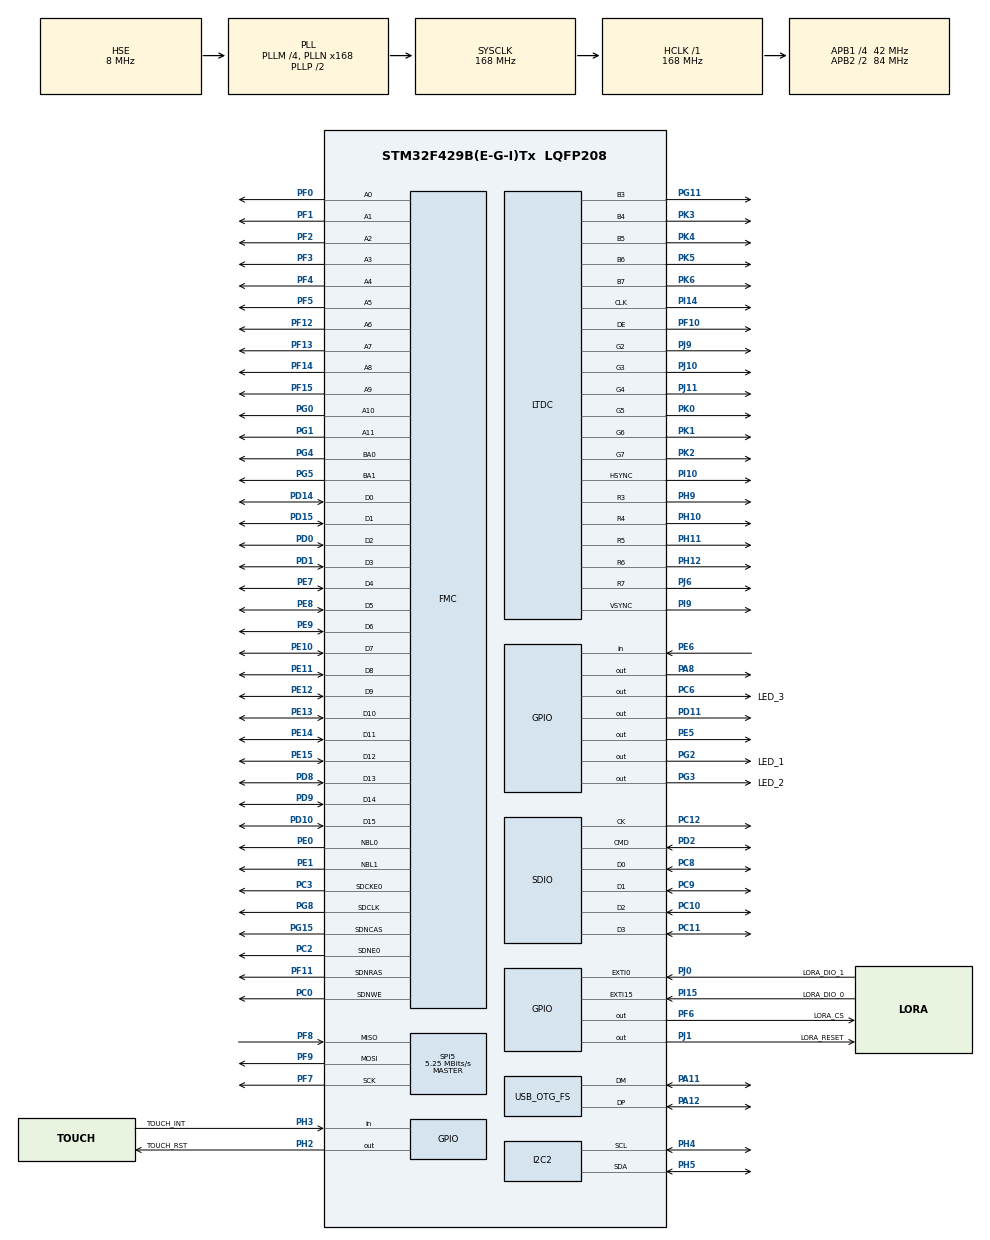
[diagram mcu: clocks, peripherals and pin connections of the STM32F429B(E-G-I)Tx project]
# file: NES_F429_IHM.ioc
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FATFS.BSP.number=1
FATFS0.BSP.STBoard=false
FATFS0.BSP.api=Unknown
FATFS0.BSP.instance=PE6
FATFS0.BSP.ip=GPIO
FATFS0.BSP.mode=Input
FATFS0.BSP.name=Detect_SDIO
FATFS0.BSP.solution=PE6
FMC.CASLatency1=FMC_SDRAM_CAS_LATENCY_3
FMC.ExitSelfRefreshDelay1=7
FMC.LoadToActiveDelay1=2
FMC.RCDDelay1=2
FMC.RPDelay1=2
FMC.RPDelay2=2
FMC.ReadPipeDelay1=FMC_SDRAM_RPIPE_DELAY_1
FMC.ReadPipeDelay2=FMC_SDRAM_RPIPE_DELAY_1
FMC.RowCycleDelay1=6
FMC.RowCycleDelay2=6
FMC.SDClockPeriod1=FMC_SDRAM_CLOCK_PERIOD_2
FMC.SDClockPeriod2=FMC_SDRAM_CLOCK_PERIOD_2
FMC.SelfRefreshTime1=4
FMC.WriteRecoveryTime1=2
I2C2.I2C_Mode=I2C_Fast
LTDC.ActiveH=272
LTDC.ActiveW=480
LTDC.Alpha_L0=255
LTDC.FBStartAdress_L0=0xC0000000
LTDC.HBP=2
LTDC.HFP=2
LTDC.HSync=17
LTDC.ImageHeight_L0=272
LTDC.ImageWidth_L0=480
LTDC.Layers=0
LTDC.PixelFormat_L0=LTDC_PIXEL_FORMAT_RGB565
LTDC.VBP=2
LTDC.VFP=2
LTDC.VSync=60
LTDC.WindowX1_L0=480
LTDC.WindowY1_L0=272
Mcu.Family=STM32F4
Mcu.Name=STM32F429B(E-G-I)Tx
Mcu.Package=LQFP208
NVIC.EXTI0_IRQn=true\:0\:0\:false\:false\:true\:true\:true\:true
NVIC.EXTI15_10_IRQn=true\:0\:0\:false\:false\:true\:true\:true\:true
NVIC.OTG_FS_IRQn=true\:0\:0\:false\:false\:true\:false\:true\:true
NVIC.PriorityGroup=NVIC_PRIORITYGROUP_4
NVIC.TIM8_TRG_COM_TIM14_IRQn=true\:15\:0\:false\:false\:true\:false\:true\:true
NVIC.TimeBase=TIM8_TRG_COM_TIM14_IRQn
NVIC.TimeBaseIP=TIM14
PA11.Mode=Host_Only
PA11.Signal=USB_OTG_FS_DM
PA12.Mode=Host_Only
PA12.Signal=USB_OTG_FS_DP
PA13.Mode=Serial_Wire
PA13.Signal=SYS_JTMS-SWDIO
PA14.Mode=Serial_Wire
PA14.Signal=SYS_JTCK-SWCLK
PA8.PinState=GPIO_PIN_SET
PA8.Signal=GPIO_Output
PC0.Signal=FMC_SDNWE
PC10.Mode=SD_4_bits_Wide_bus
PC10.Signal=SDIO_D2
PC11.Mode=SD_4_bits_Wide_bus
PC11.Signal=SDIO_D3
PC12.Mode=SD_4_bits_Wide_bus
PC12.Signal=SDIO_CK
PC2.Mode=SdramChipSelect1_1
PC2.Signal=FMC_SDNE0
PC3.Mode=SdramChipSelect1_1
PC3.Signal=FMC_SDCKE0
PC6.GPIO_Label=LED_3
PC6.Signal=GPIO_Output
PC8.Mode=SD_4_bits_Wide_bus
PC8.Signal=SDIO_D0
PC9.Mode=SD_4_bits_Wide_bus
PC9.Signal=SDIO_D1
PD0.Signal=FMC_D2_DA2
PD1.Signal=FMC_D3_DA3
PD10.Signal=FMC_D15_DA15
PD11.PinState=GPIO_PIN_SET
PD11.Signal=GPIO_Output
PD14.Signal=FMC_D0_DA0
PD15.Signal=FMC_D1_DA1
PD2.Mode=SD_4_bits_Wide_bus
PD2.Signal=SDIO_CMD
PD8.Signal=FMC_D13_DA13
PD9.Signal=FMC_D14_DA14
PE0.Signal=FMC_NBL0
PE1.Signal=FMC_NBL1
PE10.Signal=FMC_D7_DA7
PE11.Signal=FMC_D8_DA8
PE12.Signal=FMC_D9_DA9
PE13.Signal=FMC_D10_DA10
PE14.Signal=FMC_D11_DA11
PE15.Signal=FMC_D12_DA12
PE5.Signal=GPIO_Output
PE6.Signal=GPIO_Input
PE7.Signal=FMC_D4_DA4
PE8.Signal=FMC_D5_DA5
PE9.Signal=FMC_D6_DA6
PF0.Signal=FMC_A0
PF1.Signal=FMC_A1
PF10.GPIO_Speed=GPIO_SPEED_FREQ_VERY_HIGH
PF10.Mode=RGB565
PF10.Signal=LTDC_DE
PF11.Signal=FMC_SDNRAS
PF12.Signal=FMC_A6
PF13.Signal=FMC_A7
PF14.Signal=FMC_A8
PF15.Signal=FMC_A9
PF2.Signal=FMC_A2
PF3.Signal=FMC_A3
PF4.Signal=FMC_A4
PF5.Signal=FMC_A5
PF6.GPIO_Label=LORA_CS
PF6.Signal=GPIO_Output
PF7.GPIO_PuPd=GPIO_PULLUP
PF7.Mode=Full_Duplex_Master
PF7.Signal=SPI5_SCK
PF8.GPIO_PuPd=GPIO_PULLUP
PF8.Mode=Full_Duplex_Master
PF8.Signal=SPI5_MISO
PF9.GPIO_PuPd=GPIO_PULLUP
PF9.Mode=Full_Duplex_Master
PF9.Signal=SPI5_MOSI
PG0.Signal=FMC_A10
PG1.Signal=FMC_A11
PG11.GPIO_Speed=GPIO_SPEED_FREQ_VERY_HIGH
PG11.Mode=RGB565
PG11.Signal=LTDC_B3
PG15.Signal=FMC_SDNCAS
PG2.GPIO_Label=LED_1
PG2.Signal=GPIO_Output
PG3.GPIO_Label=LED_2
PG3.Signal=GPIO_Output
PG4.Signal=FMC_A14_BA0
PG5.Signal=FMC_A15_BA1
PG8.Signal=FMC_SDCLK
PH0/OSC_IN.Mode=HSE-External-Oscillator
PH0/OSC_IN.Signal=RCC_OSC_IN
PH1/OSC_OUT.Mode=HSE-External-Oscillator
PH1/OSC_OUT.Signal=RCC_OSC_OUT
PH10.GPIO_Speed=GPIO_SPEED_FREQ_VERY_HIGH
PH10.Mode=RGB565
PH10.Signal=LTDC_R4
PH11.GPIO_Speed=GPIO_SPEED_FREQ_VERY_HIGH
PH11.Mode=RGB565
PH11.Signal=LTDC_R5
PH12.GPIO_Speed=GPIO_SPEED_FREQ_VERY_HIGH
PH12.Mode=RGB565
PH12.Signal=LTDC_R6
PH2.GPIO_Label=TOUCH_RST
PH2.Signal=GPIO_Output
PH3.GPIO_Label=TOUCH_INT
PH3.Signal=GPIO_Input
PH4.GPIO_Pu=GPIO_PULLUP
PH4.Mode=I2C
PH4.Signal=I2C2_SCL
PH5.GPIO_Pu=GPIO_PULLUP
PH5.Mode=I2C
PH5.Signal=I2C2_SDA
PH9.GPIO_Speed=GPIO_SPEED_FREQ_VERY_HIGH
PH9.Mode=RGB565
PH9.Signal=LTDC_R3
PI10.GPIO_Speed=GPIO_SPEED_FREQ_VERY_HIGH
PI10.Mode=RGB565
PI10.Signal=LTDC_HSYNC
PI14.GPIO_Speed=GPIO_SPEED_FREQ_VERY_HIGH
PI14.Mode=RGB565
PI14.Signal=LTDC_CLK
PI15.GPIO_Label=LORA_DIO_0
PI15.Signal=GPXTI15
PI9.GPIO_Speed=GPIO_SPEED_FREQ_VERY_HIGH
PI9.Mode=RGB565
PI9.Signal=LTDC_VSYNC
PJ0.GPIO_Label=LORA_DIO_1
PJ0.Signal=GPXTI0
PJ1.GPIO_Label=LORA_RESET
PJ1.Signal=GPIO_Output
PJ10.GPIO_Speed=GPIO_SPEED_FREQ_VERY_HIGH
PJ10.Mode=RGB565
PJ10.Signal=LTDC_G3
PJ11.GPIO_Speed=GPIO_SPEED_FREQ_VERY_HIGH
PJ11.Mode=RGB565
PJ11.Signal=LTDC_G4
PJ6.GPIO_Speed=GPIO_SPEED_FREQ_VERY_HIGH
PJ6.Mode=RGB565
PJ6.Signal=LTDC_R7
PJ9.GPIO_Speed=GPIO_SPEED_FREQ_VERY_HIGH
PJ9.Mode=RGB565
PJ9.Signal=LTDC_G2
PK0.GPIO_Speed=GPIO_SPEED_FREQ_VERY_HIGH
PK0.Mode=RGB565
PK0.Signal=LTDC_G5
PK1.GPIO_Speed=GPIO_SPEED_FREQ_VERY_HIGH
PK1.Mode=RGB565
PK1.Signal=LTDC_G6
PK2.GPIO_Speed=GPIO_SPEED_FREQ_VERY_HIGH
PK2.Mode=RGB565
PK2.Signal=LTDC_G7
PK3.GPIO_Speed=GPIO_SPEED_FREQ_VERY_HIGH
PK3.Mode=RGB565
PK3.Signal=LTDC_B4
PK4.GPIO_Speed=GPIO_SPEED_FREQ_VERY_HIGH
PK4.Mode=RGB565
PK4.Signal=LTDC_B5
PK5.GPIO_Speed=GPIO_SPEED_FREQ_VERY_HIGH
PK5.Mode=RGB565
PK5.Signal=LTDC_B6
PK6.GPIO_Speed=GPIO_SPEED_FREQ_VERY_HIGH
PK6.Mode=RGB565
PK6.Signal=LTDC_B7
ProjectManager.HeapSize=0x200
ProjectManager.StackSize=0x400
ProjectManager.TargetToolchain=STM32CubeIDE
RCC.48MHZClocksFreq_Value=48000000
RCC.AHBFreq_Value=168000000
RCC.APB1CLKDivider=RCC_HCLK_DIV4
RCC.APB1Freq_Value=42000000
RCC.APB1TimFreq_Value=84000000
RCC.APB2CLKDivider=RCC_HCLK_DIV2
RCC.APB2Freq_Value=84000000
RCC.APB2TimFreq_Value=168000000
RCC.CortexFreq_Value=168000000
RCC.HCLKFreq_Value=168000000
RCC.HSE_VALUE=8000000
RCC.HSI_VALUE=16000000
RCC.LSE_VALUE=32768
RCC.PLLM=4
RCC.PLLN=168
RCC.PLLQ=7
RCC.PLLSAIDivR=RCC_PLLSAIDIVR_4
RCC.PLLSAIN=80
RCC.PLLSAIR=4
RCC.PWREXT_OverDrive=PWREXT_OverDrive_ACTIVATED
RCC.PWR_Regulator_Voltage_Scale=PWR_REGULATOR_VOLTAGE_SCALE1
RCC.SYSCLKFreq_VALUE=168000000
RCC.SYSCLKSource=RCC_SYSCLKSOURCE_PLLCLK
RCC.VCOOutputFreq_Value=336000000
SDIO.ClockDiv=10
SH.FMC_A0.0=FMC_A0,12b-sda1
SH.FMC_A1.0=FMC_A1,12b-sda1
SH.FMC_A10.0=FMC_A10,12b-sda1
SH.FMC_A11.0=FMC_A11,12b-sda1
SH.FMC_A14_BA0.0=FMC_BA0,FourSdramBanks1
SH.FMC_A15_BA1.0=FMC_BA1,FourSdramBanks1
SH.FMC_A2.0=FMC_A2,12b-sda1
SH.FMC_A3.0=FMC_A3,12b-sda1
SH.FMC_A4.0=FMC_A4,12b-sda1
SH.FMC_A5.0=FMC_A5,12b-sda1
SH.FMC_A6.0=FMC_A6,12b-sda1
SH.FMC_A7.0=FMC_A7,12b-sda1
SH.FMC_A8.0=FMC_A8,12b-sda1
SH.FMC_A9.0=FMC_A9,12b-sda1
SH.FMC_D0_DA0.0=FMC_D0,sd-16b-d1
SH.FMC_D10_DA10.0=FMC_D10,sd-16b-d1
SH.FMC_D11_DA11.0=FMC_D11,sd-16b-d1
SH.FMC_D12_DA12.0=FMC_D12,sd-16b-d1
SH.FMC_D13_DA13.0=FMC_D13,sd-16b-d1
SH.FMC_D14_DA14.0=FMC_D14,sd-16b-d1
SH.FMC_D15_DA15.0=FMC_D15,sd-16b-d1
SH.FMC_D1_DA1.0=FMC_D1,sd-16b-d1
SH.FMC_D2_DA2.0=FMC_D2,sd-16b-d1
SH.FMC_D3_DA3.0=FMC_D3,sd-16b-d1
SH.FMC_D4_DA4.0=FMC_D4,sd-16b-d1
SH.FMC_D5_DA5.0=FMC_D5,sd-16b-d1
SH.FMC_D6_DA6.0=FMC_D6,sd-16b-d1
SH.FMC_D7_DA7.0=FMC_D7,sd-16b-d1
SH.FMC_D8_DA8.0=FMC_D8,sd-16b-d1
SH.FMC_D9_DA9.0=FMC_D9,sd-16b-d1
SH.FMC_NBL0.0=FMC_NBL0,Sd2ByteEnable1
SH.FMC_NBL1.0=FMC_NBL1,Sd2ByteEnable1
SH.FMC_SDCLK.0=FMC_SDCLK,12b-sda1
SH.FMC_SDNCAS.0=FMC_SDNCAS,12b-sda1
SH.FMC_SDNRAS.0=FMC_SDNRAS,12b-sda1
SH.FMC_SDNWE.0=FMC_SDNWE,12b-sda1
SPI5.BaudRatePrescaler=SPI_BAUDRATEPRESCALER_16
SPI5.CalculateBaudRate=5.25 MBits/s
SPI5.Direction=SPI_DIRECTION_2LINES
SPI5.Mode=SPI_MODE_MASTER
SPI5.VirtualType=VM_MASTER
USB_HOST.BSP.number=1
USB_HOST.USBH_HandleTypeDef-ALL_Classes_FS=hUsbHostFS
USB_HOST.VirtualModeFS=All_Classes
USB_HOST0.BSP.STBoard=false
USB_HOST0.BSP.api=Unknown
USB_HOST0.BSP.instance=PE5
USB_HOST0.BSP.ip=GPIO
USB_HOST0.BSP.mode=Output
USB_HOST0.BSP.name=Drive_VBUS_FS
USB_HOST0.BSP.solution=PE5
USB_OTG_FS.VirtualMode=Host_Only
USB_OTG_FS.phy_itface=HCD_PHY_EMBEDDED
VP_FATFS_VS_SDIO.Mode=SDIO
VP_SYS_VS_tim14.Mode=TIM14
VP_USB_HOST_VS_USB_HOST_ALL_CLASS_FS.Mode=ALL_Classes_FS
board=custom

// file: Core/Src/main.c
/* USER CODE BEGIN Header */
/**
 ******************************************************************************
 * @file           : main.c
 * @brief          : Main program body
 ******************************************************************************
 * @attention
 *
 * Copyright (c) 2022 STMicroelectronics.
 * All rights reserved.
 *
 * This software is licensed under terms that can be found in the LICENSE file
 * in the root directory of this software component.
 * If no LICENSE file comes with this software, it is provided AS-IS.
 *
 ******************************************************************************
 */
/* USER CODE END Header */
#include "main.h"
#include "fatfs.h"
#include "usb_host.h"

/* USER CODE BEGIN Includes */
#include <stdlib.h>
#include <stdbool.h>
#include <stdint.h>
#include <stdarg.h>
#include <string.h>
#include "ReturnCode.h"
#include "nes.h"
#include "fatfs.h"
/* USER CODE END Includes */

I2C_HandleTypeDef hi2c2;

LTDC_HandleTypeDef hltdc;

SD_HandleTypeDef hsd;

SPI_HandleTypeDef hspi5;

SDRAM_HandleTypeDef hsdram1;

/* USER CODE BEGIN PV */
extern uint16_t * framebuffer;

/* USER CODE END PV */

void SystemClock_Config(void);
static void MX_GPIO_Init(void);
static void MX_FMC_Init(void);
static void MX_LTDC_Init(void);
static void MX_I2C2_Init(void);
static void MX_SPI5_Init(void);
static void MX_SDIO_SD_Init(void);
void MX_USB_HOST_Process(void);

/* USER CODE BEGIN PFP */
extern const uint8_t MAIO[];
static FRESULT fr;
/* USER CODE END PFP */

int main(void)
{

  /* MCU Configuration--------------------------------------------------------*/

  /* Reset of all peripherals, Initializes the Flash interface and the Systick. */
  HAL_Init();

  /* Configure the system clock */
  SystemClock_Config();

  /* Initialize all configured peripherals */
  MX_GPIO_Init();
  MX_FMC_Init();
  MX_LTDC_Init();
  MX_I2C2_Init();
  MX_SPI5_Init();
  MX_SDIO_SD_Init();
  MX_FATFS_Init();
  MX_USB_HOST_Init();
  /* USER CODE BEGIN 2 */
  fr = f_mount(&SDFatFS, "", 0);

  for(int y = 0; y < 272; y++)
  {
	  for(int x = 0; x < 480; x++)
	  {
		  framebuffer[y * 480 + x] = 0;
	  }
  }

  nofrendo_start(MAIO, NES_NTSC, 6000, 0);

  /* USER CODE END 2 */

  /* Infinite loop */
  /* USER CODE BEGIN WHILE */
	while (1)
	{

		//nes_emulate();
    /* USER CODE END WHILE */
    MX_USB_HOST_Process();

	}
}

void SystemClock_Config(void)
{
  RCC_OscInitTypeDef RCC_OscInitStruct = {0};
  RCC_ClkInitTypeDef RCC_ClkInitStruct = {0};

  /** Configure the main internal regulator output voltage
  */
  __HAL_RCC_PWR_CLK_ENABLE();
  __HAL_PWR_VOLTAGESCALING_CONFIG(PWR_REGULATOR_VOLTAGE_SCALE1);

  /** Initializes the RCC Oscillators according to the specified parameters
  * in the RCC_OscInitTypeDef structure.
  */
  RCC_OscInitStruct.OscillatorType = RCC_OSCILLATORTYPE_HSE;
  RCC_OscInitStruct.HSEState = RCC_HSE_ON;
  RCC_OscInitStruct.PLL.PLLState = RCC_PLL_ON;
  RCC_OscInitStruct.PLL.PLLSource = RCC_PLLSOURCE_HSE;
  RCC_OscInitStruct.PLL.PLLM = 4;
  RCC_OscInitStruct.PLL.PLLN = 168;
  RCC_OscInitStruct.PLL.PLLP = RCC_PLLP_DIV2;
  RCC_OscInitStruct.PLL.PLLQ = 7;
  if (HAL_RCC_OscConfig(&RCC_OscInitStruct) != HAL_OK)
  {
    Error_Handler();
  }

  /** Activate the Over-Drive mode
  */
  if (HAL_PWREx_EnableOverDrive() != HAL_OK)
  {
    Error_Handler();
  }

  /** Initializes the CPU, AHB and APB buses clocks
  */
  RCC_ClkInitStruct.ClockType = RCC_CLOCKTYPE_HCLK|RCC_CLOCKTYPE_SYSCLK
                              |RCC_CLOCKTYPE_PCLK1|RCC_CLOCKTYPE_PCLK2;
  RCC_ClkInitStruct.SYSCLKSource = RCC_SYSCLKSOURCE_PLLCLK;
  RCC_ClkInitStruct.AHBCLKDivider = RCC_SYSCLK_DIV1;
  RCC_ClkInitStruct.APB1CLKDivider = RCC_HCLK_DIV4;
  RCC_ClkInitStruct.APB2CLKDivider = RCC_HCLK_DIV2;

  if (HAL_RCC_ClockConfig(&RCC_ClkInitStruct, FLASH_LATENCY_5) != HAL_OK)
  {
    Error_Handler();
  }
}

static void MX_I2C2_Init(void)
{

  hi2c2.Instance = I2C2;
  hi2c2.Init.ClockSpeed = 400000;
  hi2c2.Init.DutyCycle = I2C_DUTYCYCLE_2;
  hi2c2.Init.OwnAddress1 = 0;
  hi2c2.Init.AddressingMode = I2C_ADDRESSINGMODE_7BIT;
  hi2c2.Init.DualAddressMode = I2C_DUALADDRESS_DISABLE;
  hi2c2.Init.OwnAddress2 = 0;
  hi2c2.Init.GeneralCallMode = I2C_GENERALCALL_DISABLE;
  hi2c2.Init.NoStretchMode = I2C_NOSTRETCH_DISABLE;
  if (HAL_I2C_Init(&hi2c2) != HAL_OK)
  {
    Error_Handler();
  }

  /** Configure Analogue filter
  */
  if (HAL_I2CEx_ConfigAnalogFilter(&hi2c2, I2C_ANALOGFILTER_ENABLE) != HAL_OK)
  {
    Error_Handler();
  }

  /** Configure Digital filter
  */
  if (HAL_I2CEx_ConfigDigitalFilter(&hi2c2, 0) != HAL_OK)
  {
    Error_Handler();
  }

}

static void MX_LTDC_Init(void)
{

  LTDC_LayerCfgTypeDef pLayerCfg = {0};

  hltdc.Instance = LTDC;
  hltdc.Init.HSPolarity = LTDC_HSPOLARITY_AL;
  hltdc.Init.VSPolarity = LTDC_VSPOLARITY_AL;
  hltdc.Init.DEPolarity = LTDC_DEPOLARITY_AL;
  hltdc.Init.PCPolarity = LTDC_PCPOLARITY_IPC;
  hltdc.Init.HorizontalSync = 16;
  hltdc.Init.VerticalSync = 59;
  hltdc.Init.AccumulatedHBP = 18;
  hltdc.Init.AccumulatedVBP = 61;
  hltdc.Init.AccumulatedActiveW = 498;
  hltdc.Init.AccumulatedActiveH = 333;
  hltdc.Init.TotalWidth = 500;
  hltdc.Init.TotalHeigh = 335;
  hltdc.Init.Backcolor.Blue = 0;
  hltdc.Init.Backcolor.Green = 0;
  hltdc.Init.Backcolor.Red = 0;
  if (HAL_LTDC_Init(&hltdc) != HAL_OK)
  {
    Error_Handler();
  }
  pLayerCfg.WindowX0 = 0;
  pLayerCfg.WindowX1 = 480;
  pLayerCfg.WindowY0 = 0;
  pLayerCfg.WindowY1 = 272;
  pLayerCfg.PixelFormat = LTDC_PIXEL_FORMAT_RGB565;
  pLayerCfg.Alpha = 255;
  pLayerCfg.Alpha0 = 0;
  pLayerCfg.BlendingFactor1 = LTDC_BLENDING_FACTOR1_CA;
  pLayerCfg.BlendingFactor2 = LTDC_BLENDING_FACTOR2_CA;
  pLayerCfg.FBStartAdress = 0xC0000000;
  pLayerCfg.ImageWidth = 480;
  pLayerCfg.ImageHeight = 272;
  pLayerCfg.Backcolor.Blue = 0;
  pLayerCfg.Backcolor.Green = 0;
  pLayerCfg.Backcolor.Red = 0;
  if (HAL_LTDC_ConfigLayer(&hltdc, &pLayerCfg, 0) != HAL_OK)
  {
    Error_Handler();
  }

}

static void MX_SDIO_SD_Init(void)
{

  hsd.Instance = SDIO;
  hsd.Init.ClockEdge = SDIO_CLOCK_EDGE_RISING;
  hsd.Init.ClockBypass = SDIO_CLOCK_BYPASS_DISABLE;
  hsd.Init.ClockPowerSave = SDIO_CLOCK_POWER_SAVE_DISABLE;
  hsd.Init.BusWide = SDIO_BUS_WIDE_1B;
  hsd.Init.HardwareFlowControl = SDIO_HARDWARE_FLOW_CONTROL_DISABLE;
  hsd.Init.ClockDiv = 10;

}

static void MX_SPI5_Init(void)
{

  /* SPI5 parameter configuration*/
  hspi5.Instance = SPI5;
  hspi5.Init.Mode = SPI_MODE_MASTER;
  hspi5.Init.Direction = SPI_DIRECTION_2LINES;
  hspi5.Init.DataSize = SPI_DATASIZE_8BIT;
  hspi5.Init.CLKPolarity = SPI_POLARITY_LOW;
  hspi5.Init.CLKPhase = SPI_PHASE_1EDGE;
  hspi5.Init.NSS = SPI_NSS_SOFT;
  hspi5.Init.BaudRatePrescaler = SPI_BAUDRATEPRESCALER_16;
  hspi5.Init.FirstBit = SPI_FIRSTBIT_MSB;
  hspi5.Init.TIMode = SPI_TIMODE_DISABLE;
  hspi5.Init.CRCCalculation = SPI_CRCCALCULATION_DISABLE;
  hspi5.Init.CRCPolynomial = 10;
  if (HAL_SPI_Init(&hspi5) != HAL_OK)
  {
    Error_Handler();
  }

}

/* FMC initialization function */
static void MX_FMC_Init(void)
{

  /* USER CODE BEGIN FMC_Init 0 */
#define REFRESH_COUNT        683
#define SDRAM_TIMEOUT                            ((uint32_t)0xFFFF)
#define SDRAM_MODEREG_BURST_LENGTH_1             ((uint16_t)0x0000)
#define SDRAM_MODEREG_BURST_LENGTH_2             ((uint16_t)0x0001)
#define SDRAM_MODEREG_BURST_LENGTH_4             ((uint16_t)0x0002)
#define SDRAM_MODEREG_BURST_LENGTH_8             ((uint16_t)0x0004)
#define SDRAM_MODEREG_BURST_TYPE_SEQUENTIAL      ((uint16_t)0x0000)
#define SDRAM_MODEREG_BURST_TYPE_INTERLEAVED     ((uint16_t)0x0008)
#define SDRAM_MODEREG_CAS_LATENCY_2              ((uint16_t)0x0020)
#define SDRAM_MODEREG_CAS_LATENCY_3              ((uint16_t)0x0030)
#define SDRAM_MODEREG_OPERATING_MODE_STANDARD    ((uint16_t)0x0000)
#define SDRAM_MODEREG_WRITEBURST_MODE_PROGRAMMED ((uint16_t)0x0000)
#define SDRAM_MODEREG_WRITEBURST_MODE_SINGLE     ((uint16_t)0x0200)
  /* USER CODE END FMC_Init 0 */

  FMC_SDRAM_TimingTypeDef SdramTiming = {0};

  /* USER CODE BEGIN FMC_Init 1 */
	FMC_SDRAM_CommandTypeDef Command;
  /* USER CODE END FMC_Init 1 */

  /** Perform the SDRAM1 memory initialization sequence
  */
  hsdram1.Instance = FMC_SDRAM_DEVICE;
  /* hsdram1.Init */
  hsdram1.Init.SDBank = FMC_SDRAM_BANK1;
  hsdram1.Init.ColumnBitsNumber = FMC_SDRAM_COLUMN_BITS_NUM_8;
  hsdram1.Init.RowBitsNumber = FMC_SDRAM_ROW_BITS_NUM_12;
  hsdram1.Init.MemoryDataWidth = FMC_SDRAM_MEM_BUS_WIDTH_16;
  hsdram1.Init.InternalBankNumber = FMC_SDRAM_INTERN_BANKS_NUM_4;
  hsdram1.Init.CASLatency = FMC_SDRAM_CAS_LATENCY_3;
  hsdram1.Init.WriteProtection = FMC_SDRAM_WRITE_PROTECTION_DISABLE;
  hsdram1.Init.SDClockPeriod = FMC_SDRAM_CLOCK_PERIOD_2;
  hsdram1.Init.ReadBurst = FMC_SDRAM_RBURST_DISABLE;
  hsdram1.Init.ReadPipeDelay = FMC_SDRAM_RPIPE_DELAY_1;
  /* SdramTiming */
  SdramTiming.LoadToActiveDelay = 2;
  SdramTiming.ExitSelfRefreshDelay = 7;
  SdramTiming.SelfRefreshTime = 4;
  SdramTiming.RowCycleDelay = 6;
  SdramTiming.WriteRecoveryTime = 2;
  SdramTiming.RPDelay = 2;
  SdramTiming.RCDDelay = 2;

  if (HAL_SDRAM_Init(&hsdram1, &SdramTiming) != HAL_OK)
  {
    Error_Handler( );
  }

  /* USER CODE BEGIN FMC_Init 2 */
	__IO uint32_t tmpmrd = 0;

	/* Step 1: Configure a clock configuration enable command */
	Command.CommandMode            = FMC_SDRAM_CMD_CLK_ENABLE;
	Command.CommandTarget          =  FMC_SDRAM_CMD_TARGET_BANK1;
	Command.AutoRefreshNumber      = 1;
	Command.ModeRegisterDefinition = 0;

	/* Send the command */
	HAL_SDRAM_SendCommand(&hsdram1, &Command, SDRAM_TIMEOUT);

	/* Step 2: Insert 100 us minimum delay */
	/* Inserted delay is equal to 1 ms due to systick time base unit (ms) */
	HAL_Delay(1);

	/* Step 3: Configure a PALL (precharge all) command */
	Command.CommandMode            = FMC_SDRAM_CMD_PALL;
	Command.CommandTarget          = FMC_SDRAM_CMD_TARGET_BANK1;
	Command.AutoRefreshNumber      = 1;
	Command.ModeRegisterDefinition = 0;

	/* Send the command */
	HAL_SDRAM_SendCommand(&hsdram1, &Command, SDRAM_TIMEOUT);

	/* Step 4: Configure an Auto Refresh command */
	Command.CommandMode            = FMC_SDRAM_CMD_AUTOREFRESH_MODE;
	Command.CommandTarget          = FMC_SDRAM_CMD_TARGET_BANK1;
	Command.AutoRefreshNumber      = 4;
	Command.ModeRegisterDefinition = 0;

	/* Send the command */
	HAL_SDRAM_SendCommand(&hsdram1, &Command, SDRAM_TIMEOUT);

	/* Step 5: Program the external memory mode register */
	tmpmrd = (uint32_t)SDRAM_MODEREG_BURST_LENGTH_2 | \
			SDRAM_MODEREG_BURST_TYPE_SEQUENTIAL    | \
			SDRAM_MODEREG_CAS_LATENCY_3            | \
			SDRAM_MODEREG_OPERATING_MODE_STANDARD  | \
			SDRAM_MODEREG_WRITEBURST_MODE_SINGLE;

	Command.CommandMode            = FMC_SDRAM_CMD_LOAD_MODE;
	Command.CommandTarget          = FMC_SDRAM_CMD_TARGET_BANK1;
	Command.AutoRefreshNumber      = 1;
	Command.ModeRegisterDefinition = tmpmrd;

	/* Send the command */
	HAL_SDRAM_SendCommand(&hsdram1, &Command, SDRAM_TIMEOUT);

	/* Step 6: Set the refresh rate counter */
	/* Set the device refresh rate */
	HAL_SDRAM_ProgramRefreshRate(&hsdram1, REFRESH_COUNT);
	//Deactivate speculative/cache access to first FMC Bank to save FMC bandwidth
	//FMC_Bank1->BTCR[0] = 0x000030D2;
  /* USER CODE END FMC_Init 2 */
}

static void MX_GPIO_Init(void)
{
  GPIO_InitTypeDef GPIO_InitStruct = {0};

  /* GPIO Ports Clock Enable */
  __HAL_RCC_GPIOE_CLK_ENABLE();
  __HAL_RCC_GPIOI_CLK_ENABLE();
  __HAL_RCC_GPIOC_CLK_ENABLE();
  __HAL_RCC_GPIOF_CLK_ENABLE();
  __HAL_RCC_GPIOH_CLK_ENABLE();
  __HAL_RCC_GPIOA_CLK_ENABLE();
  __HAL_RCC_GPIOB_CLK_ENABLE();
  __HAL_RCC_GPIOJ_CLK_ENABLE();
  __HAL_RCC_GPIOG_CLK_ENABLE();
  __HAL_RCC_GPIOD_CLK_ENABLE();
  __HAL_RCC_GPIOK_CLK_ENABLE();

  /*Configure GPIO pin Output Level */
  HAL_GPIO_WritePin(GPIOE, GPIO_PIN_5, GPIO_PIN_RESET);

  /*Configure GPIO pin Output Level */
  HAL_GPIO_WritePin(LORA_CS_GPIO_Port, LORA_CS_Pin, GPIO_PIN_RESET);

  /*Configure GPIO pin Output Level */
  HAL_GPIO_WritePin(TOUCH_RST_GPIO_Port, TOUCH_RST_Pin, GPIO_PIN_RESET);

  /*Configure GPIO pin Output Level */
  HAL_GPIO_WritePin(LORA_RESET_GPIO_Port, LORA_RESET_Pin, GPIO_PIN_RESET);

  /*Configure GPIO pin Output Level */
  HAL_GPIO_WritePin(GPIOD, GPIO_PIN_11, GPIO_PIN_SET);

  /*Configure GPIO pin Output Level */
  HAL_GPIO_WritePin(GPIOG, LED_1_Pin|LED_2_Pin, GPIO_PIN_RESET);

  /*Configure GPIO pin Output Level */
  HAL_GPIO_WritePin(LED_3_GPIO_Port, LED_3_Pin, GPIO_PIN_RESET);

  /*Configure GPIO pin Output Level */
  HAL_GPIO_WritePin(GPIOA, GPIO_PIN_8, GPIO_PIN_SET);

  /*Configure GPIO pins : PE2 PE3 PE4 */
  GPIO_InitStruct.Pin = GPIO_PIN_2|GPIO_PIN_3|GPIO_PIN_4;
  GPIO_InitStruct.Mode = GPIO_MODE_ANALOG;
  GPIO_InitStruct.Pull = GPIO_NOPULL;
  HAL_GPIO_Init(GPIOE, &GPIO_InitStruct);

  /*Configure GPIO pin : PE5 */
  GPIO_InitStruct.Pin = GPIO_PIN_5;
  GPIO_InitStruct.Mode = GPIO_MODE_OUTPUT_PP;
  GPIO_InitStruct.Pull = GPIO_NOPULL;
  GPIO_InitStruct.Speed = GPIO_SPEED_FREQ_LOW;
  HAL_GPIO_Init(GPIOE, &GPIO_InitStruct);

  /*Configure GPIO pin : PE6 */
  GPIO_InitStruct.Pin = GPIO_PIN_6;
  GPIO_InitStruct.Mode = GPIO_MODE_INPUT;
  GPIO_InitStruct.Pull = GPIO_NOPULL;
  HAL_GPIO_Init(GPIOE, &GPIO_InitStruct);

  /*Configure GPIO pins : PI8 PI11 PI12 PI13
                           PI0 PI1 PI2 PI3
                           PI4 PI5 PI6 PI7 */
  GPIO_InitStruct.Pin = GPIO_PIN_8|GPIO_PIN_11|GPIO_PIN_12|GPIO_PIN_13
                          |GPIO_PIN_0|GPIO_PIN_1|GPIO_PIN_2|GPIO_PIN_3
                          |GPIO_PIN_4|GPIO_PIN_5|GPIO_PIN_6|GPIO_PIN_7;
  GPIO_InitStruct.Mode = GPIO_MODE_ANALOG;
  GPIO_InitStruct.Pull = GPIO_NOPULL;
  HAL_GPIO_Init(GPIOI, &GPIO_InitStruct);

  /*Configure GPIO pins : PC13 PC14 PC15 PC1
                           PC4 PC5 PC7 */
  GPIO_InitStruct.Pin = GPIO_PIN_13|GPIO_PIN_14|GPIO_PIN_15|GPIO_PIN_1
                          |GPIO_PIN_4|GPIO_PIN_5|GPIO_PIN_7;
  GPIO_InitStruct.Mode = GPIO_MODE_ANALOG;
  GPIO_InitStruct.Pull = GPIO_NOPULL;
  HAL_GPIO_Init(GPIOC, &GPIO_InitStruct);

  /*Configure GPIO pin : LORA_CS_Pin */
  GPIO_InitStruct.Pin = LORA_CS_Pin;
  GPIO_InitStruct.Mode = GPIO_MODE_OUTPUT_PP;
  GPIO_InitStruct.Pull = GPIO_NOPULL;
  GPIO_InitStruct.Speed = GPIO_SPEED_FREQ_LOW;
  HAL_GPIO_Init(LORA_CS_GPIO_Port, &GPIO_InitStruct);

  /*Configure GPIO pins : PA0 PA1 PA2 PA3
                           PA4 PA5 PA6 PA7
                           PA9 PA10 PA15 */
  GPIO_InitStruct.Pin = GPIO_PIN_0|GPIO_PIN_1|GPIO_PIN_2|GPIO_PIN_3
                          |GPIO_PIN_4|GPIO_PIN_5|GPIO_PIN_6|GPIO_PIN_7
                          |GPIO_PIN_9|GPIO_PIN_10|GPIO_PIN_15;
  GPIO_InitStruct.Mode = GPIO_MODE_ANALOG;
  GPIO_InitStruct.Pull = GPIO_NOPULL;
  HAL_GPIO_Init(GPIOA, &GPIO_InitStruct);

  /*Configure GPIO pin : TOUCH_RST_Pin */
  GPIO_InitStruct.Pin = TOUCH_RST_Pin;
  GPIO_InitStruct.Mode = GPIO_MODE_OUTPUT_PP;
  GPIO_InitStruct.Pull = GPIO_NOPULL;
  GPIO_InitStruct.Speed = GPIO_SPEED_FREQ_LOW;
  HAL_GPIO_Init(TOUCH_RST_GPIO_Port, &GPIO_InitStruct);

  /*Configure GPIO pin : TOUCH_INT_Pin */
  GPIO_InitStruct.Pin = TOUCH_INT_Pin;
  GPIO_InitStruct.Mode = GPIO_MODE_INPUT;
  GPIO_InitStruct.Pull = GPIO_NOPULL;
  HAL_GPIO_Init(TOUCH_INT_GPIO_Port, &GPIO_InitStruct);

  /*Configure GPIO pins : PB0 PB1 PB2 PB10
                           PB11 PB12 PB13 PB14
                           PB15 PB3 PB4 PB5
                           PB6 PB7 PB8 PB9 */
  GPIO_InitStruct.Pin = GPIO_PIN_0|GPIO_PIN_1|GPIO_PIN_2|GPIO_PIN_10
                          |GPIO_PIN_11|GPIO_PIN_12|GPIO_PIN_13|GPIO_PIN_14
                          |GPIO_PIN_15|GPIO_PIN_3|GPIO_PIN_4|GPIO_PIN_5
                          |GPIO_PIN_6|GPIO_PIN_7|GPIO_PIN_8|GPIO_PIN_9;
  GPIO_InitStruct.Mode = GPIO_MODE_ANALOG;
  GPIO_InitStruct.Pull = GPIO_NOPULL;
  HAL_GPIO_Init(GPIOB, &GPIO_InitStruct);

  /*Configure GPIO pin : LORA_DIO_0_Pin */
  GPIO_InitStruct.Pin = LORA_DIO_0_Pin;
  GPIO_InitStruct.Mode = GPIO_MODE_IT_RISING;
  GPIO_InitStruct.Pull = GPIO_NOPULL;
  HAL_GPIO_Init(LORA_DIO_0_GPIO_Port, &GPIO_InitStruct);

  /*Configure GPIO pin : LORA_DIO_1_Pin */
  GPIO_InitStruct.Pin = LORA_DIO_1_Pin;
  GPIO_InitStruct.Mode = GPIO_MODE_IT_RISING;
  GPIO_InitStruct.Pull = GPIO_NOPULL;
  HAL_GPIO_Init(LORA_DIO_1_GPIO_Port, &GPIO_InitStruct);

  /*Configure GPIO pin : LORA_RESET_Pin */
  GPIO_InitStruct.Pin = LORA_RESET_Pin;
  GPIO_InitStruct.Mode = GPIO_MODE_OUTPUT_PP;
  GPIO_InitStruct.Pull = GPIO_NOPULL;
  GPIO_InitStruct.Speed = GPIO_SPEED_FREQ_LOW;
  HAL_GPIO_Init(LORA_RESET_GPIO_Port, &GPIO_InitStruct);

  /*Configure GPIO pins : PJ2 PJ3 PJ4 PJ5
                           PJ7 PJ8 PJ12 PJ13
                           PJ14 PJ15 */
  GPIO_InitStruct.Pin = GPIO_PIN_2|GPIO_PIN_3|GPIO_PIN_4|GPIO_PIN_5
                          |GPIO_PIN_7|GPIO_PIN_8|GPIO_PIN_12|GPIO_PIN_13
                          |GPIO_PIN_14|GPIO_PIN_15;
  GPIO_InitStruct.Mode = GPIO_MODE_ANALOG;
  GPIO_InitStruct.Pull = GPIO_NOPULL;
  HAL_GPIO_Init(GPIOJ, &GPIO_InitStruct);

  /*Configure GPIO pins : PH6 PH7 PH8 PH13
                           PH14 PH15 */
  GPIO_InitStruct.Pin = GPIO_PIN_6|GPIO_PIN_7|GPIO_PIN_8|GPIO_PIN_13
                          |GPIO_PIN_14|GPIO_PIN_15;
  GPIO_InitStruct.Mode = GPIO_MODE_ANALOG;
  GPIO_InitStruct.Pull = GPIO_NOPULL;
  HAL_GPIO_Init(GPIOH, &GPIO_InitStruct);

  /*Configure GPIO pin : PD11 */
  GPIO_InitStruct.Pin = GPIO_PIN_11;
  GPIO_InitStruct.Mode = GPIO_MODE_OUTPUT_PP;
  GPIO_InitStruct.Pull = GPIO_NOPULL;
  GPIO_InitStruct.Speed = GPIO_SPEED_FREQ_LOW;
  HAL_GPIO_Init(GPIOD, &GPIO_InitStruct);

  /*Configure GPIO pins : PD12 PD13 PD3 PD4
                           PD5 PD6 PD7 */
  GPIO_InitStruct.Pin = GPIO_PIN_12|GPIO_PIN_13|GPIO_PIN_3|GPIO_PIN_4
                          |GPIO_PIN_5|GPIO_PIN_6|GPIO_PIN_7;
  GPIO_InitStruct.Mode = GPIO_MODE_ANALOG;
  GPIO_InitStruct.Pull = GPIO_NOPULL;
  HAL_GPIO_Init(GPIOD, &GPIO_InitStruct);

  /*Configure GPIO pins : LED_1_Pin LED_2_Pin */
  GPIO_InitStruct.Pin = LED_1_Pin|LED_2_Pin;
  GPIO_InitStruct.Mode = GPIO_MODE_OUTPUT_PP;
  GPIO_InitStruct.Pull = GPIO_NOPULL;
  GPIO_InitStruct.Speed = GPIO_SPEED_FREQ_LOW;
  HAL_GPIO_Init(GPIOG, &GPIO_InitStruct);

  /*Configure GPIO pins : PG6 PG7 PG9 PG10
                           PG12 PG13 PG14 */
  GPIO_InitStruct.Pin = GPIO_PIN_6|GPIO_PIN_7|GPIO_PIN_9|GPIO_PIN_10
                          |GPIO_PIN_12|GPIO_PIN_13|GPIO_PIN_14;
  GPIO_InitStruct.Mode = GPIO_MODE_ANALOG;
  GPIO_InitStruct.Pull = GPIO_NOPULL;
  HAL_GPIO_Init(GPIOG, &GPIO_InitStruct);

  /*Configure GPIO pin : LED_3_Pin */
  GPIO_InitStruct.Pin = LED_3_Pin;
  GPIO_InitStruct.Mode = GPIO_MODE_OUTPUT_PP;
  GPIO_InitStruct.Pull = GPIO_NOPULL;
  GPIO_InitStruct.Speed = GPIO_SPEED_FREQ_LOW;
  HAL_GPIO_Init(LED_3_GPIO_Port, &GPIO_InitStruct);

  /*Configure GPIO pin : PA8 */
  GPIO_InitStruct.Pin = GPIO_PIN_8;
  GPIO_InitStruct.Mode = GPIO_MODE_OUTPUT_PP;
  GPIO_InitStruct.Pull = GPIO_NOPULL;
  GPIO_InitStruct.Speed = GPIO_SPEED_FREQ_LOW;
  HAL_GPIO_Init(GPIOA, &GPIO_InitStruct);

  /*Configure GPIO pin : PK7 */
  GPIO_InitStruct.Pin = GPIO_PIN_7;
  GPIO_InitStruct.Mode = GPIO_MODE_ANALOG;
  GPIO_InitStruct.Pull = GPIO_NOPULL;
  HAL_GPIO_Init(GPIOK, &GPIO_InitStruct);

  /* EXTI interrupt init*/
  HAL_NVIC_SetPriority(EXTI0_IRQn, 0, 0);
  HAL_NVIC_EnableIRQ(EXTI0_IRQn);

  HAL_NVIC_SetPriority(EXTI15_10_IRQn, 0, 0);
  HAL_NVIC_EnableIRQ(EXTI15_10_IRQn);

}

void HAL_TIM_PeriodElapsedCallback(TIM_HandleTypeDef *htim)
{
  if (htim->Instance == TIM14) {
    HAL_IncTick();
  }
}

void Error_Handler(void)
{
	__disable_irq();
	while (1)
	{
	}
}
